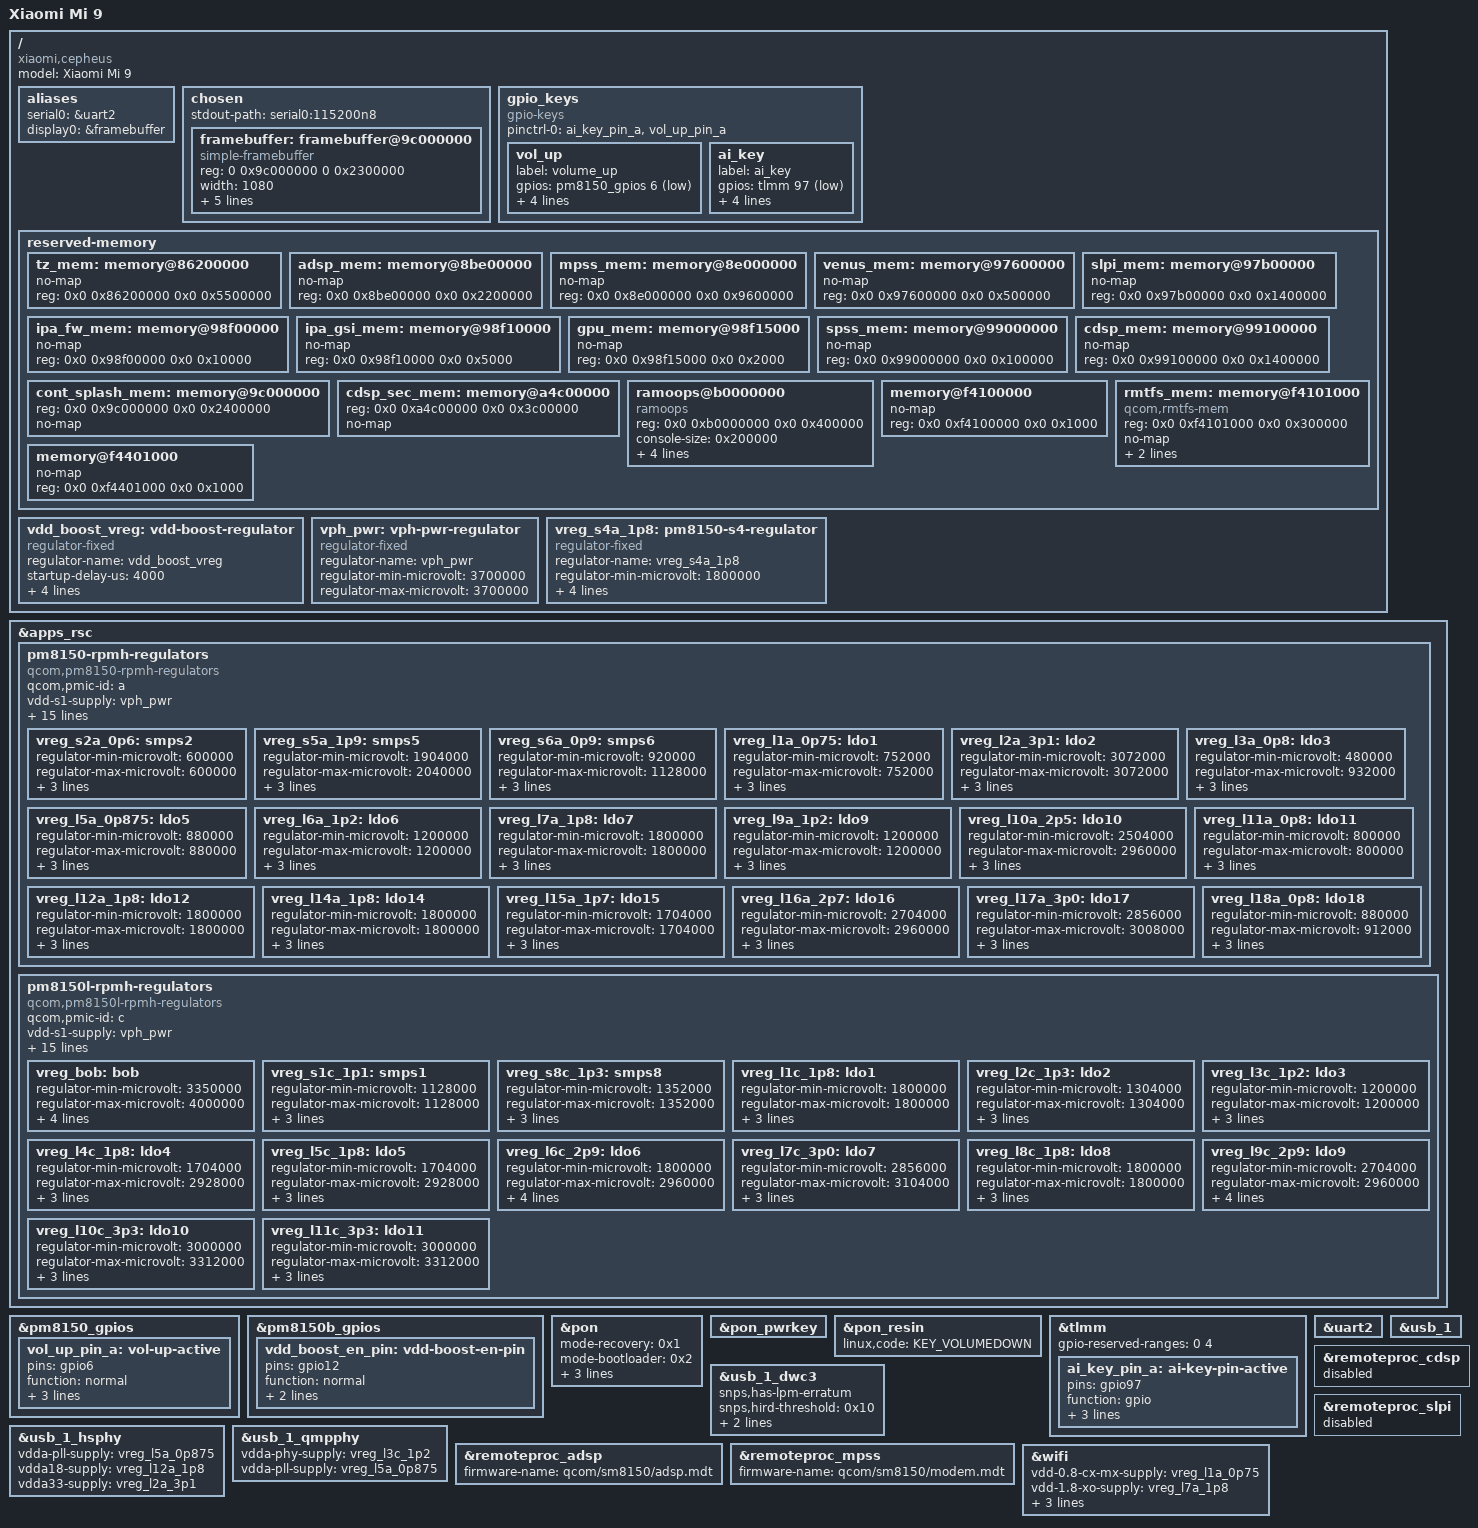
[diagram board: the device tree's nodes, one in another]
// SPDX-License-Identifier: BSD-3-Clause
/*
 * Copyright (c) 2021, Alexey Minnekhanov <alexeymin@postmarketos.org>
 */

/dts-v1/;

#include <dt-bindings/gpio/gpio.h>
#include <dt-bindings/input/input.h>
#include <dt-bindings/input/gpio-keys.h>
#include <dt-bindings/pinctrl/qcom,pmic-gpio.h>
#include <dt-bindings/regulator/qcom,rpmh-regulator.h>
#include "sm8150.dtsi"
#include "pm8150.dtsi"
#include "pm8150b.dtsi"
#include "pm8150l.dtsi"

/* 
 * Rewrite reserved memory maps inherited from sm8150.dtsi to match the ones
 * used on xiaomi-cepheus.
 * Note: this list is ordered by its memory address in sm8150.dtsi.
 */
/delete-node/ &tz_mem;      /* same address but larger, no place for rmtfs_mem! */
/delete-node/ &rmtfs_mem;   /* moved to completely different address */
/delete-node/ &adsp_mem;    /* same start address, but larger size */
/delete-node/ &mpss_mem;    /* same size, shifted higher, due to larger adsp_mem */
/delete-node/ &venus_mem;   /* same size, shifted higher */
/delete-node/ &slpi_mem;    /* same size, shifted higher */
/delete-node/ &ipa_fw_mem;  /* same size, shifted higher */
/delete-node/ &ipa_gsi_mem; /* same size, shifted higher */
/delete-node/ &gpu_mem;     /* same size, shifted higher */
/delete-node/ &spss_mem;    /* same size, shifted higher */
/delete-node/ &cdsp_mem;    /* same size, shifted higher */

/ {
	model = "Xiaomi Mi 9";
	compatible = "xiaomi,cepheus", "qcom,sm8150";

	aliases {
		serial0 = &uart2;
		display0 = &framebuffer;
	};

	chosen {
		#address-cells = <2>;
		#size-cells = <2>;
		ranges;

		stdout-path = "serial0:115200n8";

		framebuffer: framebuffer@9c000000 {
			compatible = "simple-framebuffer";
			reg = <0 0x9c000000 0 0x2300000>;
			width = <1080>;
			height = <2340>;
			stride = <(1080 * 4)>;
			format = "a8r8g8b8";
			/*
			 * That's (going to be) a lot of clocks, but it's necessary due
			 * to unused clk cleanup & no panel driver yet (& no dispcc either)..
			 */
			clocks = <&gcc GCC_DISP_HF_AXI_CLK>,
				 <&gcc GCC_DISP_SF_AXI_CLK>;
		};
	};

	gpio_keys {
		compatible = "gpio-keys";
		pinctrl-names = "default";
		pinctrl-0 = <&ai_key_pin_a &vol_up_pin_a>;
		
		vol_up {
			label = "volume_up";
			gpios = <&pm8150_gpios 6 GPIO_ACTIVE_LOW>;
			linux,input-type = <EV_KEY>;
			linux,code = <KEY_VOLUMEUP>;
			wakeup-source;
			debounce-interval = <15>;
		};

		ai_key {
			label = "ai_key";
			gpios = <&tlmm 97 GPIO_ACTIVE_LOW>;
			linux,input-type = <EV_KEY>;
			linux,code = <KEY_HOMEPAGE>; /* no AI key in Linux */
			wakeup-source;
			debounce-interval = <39>;
		};
	};

	reserved-memory {
		tz_mem: memory@86200000 {
			no-map;
			reg = <0x0 0x86200000 0x0 0x5500000>;
			phandle = <0x594>;
		};

		adsp_mem: memory@8be00000 {
			no-map;
			reg = <0x0 0x8be00000 0x0 0x2200000>;
		};

		mpss_mem: memory@8e000000 {
			no-map;
			reg = <0x0 0x8e000000 0x0 0x9600000>;
		};

		venus_mem: memory@97600000 {
			no-map;
			reg = <0x0 0x97600000 0x0 0x500000>;
		};

		slpi_mem: memory@97b00000 {
			no-map;
			reg = <0x0 0x97b00000 0x0 0x1400000>;
		};

		ipa_fw_mem: memory@98f00000 {
			no-map;
			reg = <0x0 0x98f00000 0x0 0x10000>;
		};

		ipa_gsi_mem: memory@98f10000 {
			no-map;
			reg = <0x0 0x98f10000 0x0 0x5000>;
		};

		gpu_mem: memory@98f15000 {
			no-map;
			reg = <0x0 0x98f15000 0x0 0x2000>;
		};

		spss_mem: memory@99000000 {
			no-map;
			reg = <0x0 0x99000000 0x0 0x100000>;
		};

		cdsp_mem: memory@99100000 {
			no-map;
			reg = <0x0 0x99100000 0x0 0x1400000>;
		};

		cont_splash_mem: memory@9c000000 {
			reg = <0x0 0x9c000000 0x0 0x2400000>;
			no-map;
		};

		cdsp_sec_mem: memory@a4c00000 {
			reg = <0x0 0xa4c00000 0x0 0x3c00000>;
			no-map;
		};

		ramoops@b0000000 {
			compatible = "ramoops";
			reg = <0x0 0xb0000000 0x0 0x400000>;
			console-size = <0x200000>;
			ecc-size = <0>;
			ftrace-size = <0>;
			pmsg-size = <0x200000>;
			record-size = <0>;
		};

		/* Downstream dynamically allocates rmtfs_mem region using
		 * dma_alloc_coherent and adds 4k guard pages before and after
		 * it to workaround some "XPU limitation". */
		/* rmtfs_lower_guard */
		memory@f4100000 {
			no-map;
			reg = <0x0 0xf4100000 0x0 0x1000>;
		};

		rmtfs_mem: memory@f4101000 {
			compatible = "qcom,rmtfs-mem";
			reg = <0x0 0xf4101000 0x0 0x300000>;
			no-map;

			qcom,client-id = <1>;
			qcom,vmid = <15>;
		};

		/* rmtfs_upper_guard */
		memory@f4401000 {
			no-map;
			reg = <0x0 0xf4401000 0x0 0x1000>;
		};
	};

	vdd_boost_vreg: vdd-boost-regulator {
		compatible = "regulator-fixed";
		regulator-name = "vdd_boost_vreg";
		startup-delay-us = <4000>;
		enable-active-high;
		regulator-always-on;
		gpio = <&pm8150b_gpios 5 GPIO_ACTIVE_HIGH>;
		pinctrl-names = "default";
		pinctrl-0 = <&vdd_boost_en_pin>;
	};

	vph_pwr: vph-pwr-regulator {
		compatible = "regulator-fixed";
		regulator-name = "vph_pwr";
		regulator-min-microvolt = <3700000>;
		regulator-max-microvolt = <3700000>;
	};

	/* S4 is modeled as a fixed regulator in vendor sources */
	vreg_s4a_1p8: pm8150-s4-regulator {
		compatible = "regulator-fixed";
		regulator-name = "vreg_s4a_1p8";

		regulator-min-microvolt = <1800000>;
		regulator-max-microvolt = <1800000>;

		regulator-always-on;
		regulator-boot-on;

		vin-supply = <&vph_pwr>;
	};
};

&apps_rsc {
	pm8150-rpmh-regulators {
		compatible = "qcom,pm8150-rpmh-regulators";
		qcom,pmic-id = "a";

		vdd-s1-supply = <&vph_pwr>;
		vdd-s2-supply = <&vph_pwr>;
		vdd-s3-supply = <&vph_pwr>;
		vdd-s4-supply = <&vph_pwr>;
		vdd-s5-supply = <&vph_pwr>;
		vdd-s6-supply = <&vph_pwr>;
		vdd-s7-supply = <&vph_pwr>;
		vdd-s8-supply = <&vph_pwr>;
		vdd-s9-supply = <&vph_pwr>;
		vdd-s10-supply = <&vph_pwr>;

		vdd-l1-l8-l11-supply = <&vreg_s6a_0p9>;
		vdd-l2-l10-supply = <&vreg_bob>;
		vdd-l3-l4-l5-l18-supply = <&vreg_s6a_0p9>;
		vdd-l6-l9-supply = <&vreg_s8c_1p3>;
		vdd-l7-l12-l14-l15-supply = <&vreg_s5a_1p9>;
		vdd-l13-l16-l17-supply = <&vreg_bob>;

		vreg_s2a_0p6: smps2 {
			regulator-min-microvolt = <600000>;
			regulator-max-microvolt = <600000>;
			regulator-initial-mode = <RPMH_REGULATOR_MODE_HPM>;
			regulator-name = "pm8150_s2a_0p6";
		};

		vreg_s5a_1p9: smps5 {
			regulator-min-microvolt = <1904000>;
			regulator-max-microvolt = <2040000>;
			regulator-initial-mode = <RPMH_REGULATOR_MODE_HPM>;
			regulator-name = "pm8150_s5a_0p6";
		};

		vreg_s6a_0p9: smps6 {
			regulator-min-microvolt = <920000>;
			regulator-max-microvolt = <1128000>;
			regulator-initial-mode = <RPMH_REGULATOR_MODE_HPM>;
			regulator-name = "pm8150_s6a_0p9";
		};

		vreg_l1a_0p75: ldo1 {
			regulator-min-microvolt = <752000>;
			regulator-max-microvolt = <752000>;
			regulator-initial-mode = <RPMH_REGULATOR_MODE_HPM>;
			regulator-name = "pm8150_l1a_0p75";
		};

		vreg_l2a_3p1: ldo2 {
			regulator-min-microvolt = <3072000>;
			regulator-max-microvolt = <3072000>;
			regulator-initial-mode = <RPMH_REGULATOR_MODE_HPM>;
			regulator-name = "pm8150_l2a_3p1";
		};

		vreg_l3a_0p8: ldo3 {
			regulator-min-microvolt = <480000>;
			regulator-max-microvolt = <932000>;
			regulator-initial-mode = <RPMH_REGULATOR_MODE_HPM>;
			regulator-name = "pm8150_l3a_0p8";
		};

		vreg_l5a_0p875: ldo5 {
			regulator-min-microvolt = <880000>;
			regulator-max-microvolt = <880000>;
			regulator-initial-mode = <RPMH_REGULATOR_MODE_HPM>;
			regulator-name = "pm8150_l5a_0p875";
		};

		vreg_l6a_1p2: ldo6 {
			regulator-min-microvolt = <1200000>;
			regulator-max-microvolt = <1200000>;
			regulator-initial-mode = <RPMH_REGULATOR_MODE_HPM>;
			regulator-name = "pm8150_l6a_1p2";
		};

		vreg_l7a_1p8: ldo7 {
			regulator-min-microvolt = <1800000>;
			regulator-max-microvolt = <1800000>;
			regulator-initial-mode = <RPMH_REGULATOR_MODE_HPM>;
			regulator-name = "pm8150_l7a_1p8";
		};

		vreg_l9a_1p2: ldo9 {
			regulator-min-microvolt = <1200000>;
			regulator-max-microvolt = <1200000>;
			regulator-initial-mode = <RPMH_REGULATOR_MODE_HPM>;
			regulator-name = "pm8150_l9a_1p2";
		};

		vreg_l10a_2p5: ldo10 {
			regulator-min-microvolt = <2504000>;
			regulator-max-microvolt = <2960000>;
			regulator-initial-mode = <RPMH_REGULATOR_MODE_HPM>;
			regulator-name = "pm8150_l10a_2p5";
		};

		vreg_l11a_0p8: ldo11 {
			regulator-min-microvolt = <800000>;
			regulator-max-microvolt = <800000>;
			regulator-initial-mode = <RPMH_REGULATOR_MODE_HPM>;
			regulator-name = "pm8150_l11a_0p8";
		};

		vreg_l12a_1p8: ldo12 {
			regulator-min-microvolt = <1800000>;
			regulator-max-microvolt = <1800000>;
			regulator-initial-mode = <RPMH_REGULATOR_MODE_HPM>;
			regulator-name = "pm8150_l12a_1p8";
		};

		/* L13 is unused, but min/max are 3000000 for it. */

		vreg_l14a_1p8: ldo14 {
			regulator-min-microvolt = <1800000>;
			regulator-max-microvolt = <1800000>;
			regulator-initial-mode = <RPMH_REGULATOR_MODE_HPM>;
			regulator-name = "pm8150_l14a_1p8";
		};

		vreg_l15a_1p7: ldo15 {
			regulator-min-microvolt = <1704000>;
			regulator-max-microvolt = <1704000>;
			regulator-initial-mode = <RPMH_REGULATOR_MODE_HPM>;
			regulator-name = "pm8150_l15a_1p7";
		};

		vreg_l16a_2p7: ldo16 {
			regulator-min-microvolt = <2704000>;
			regulator-max-microvolt = <2960000>;
			regulator-initial-mode = <RPMH_REGULATOR_MODE_HPM>;
			regulator-name = "pm8150_l16a_2p7";
		};

		vreg_l17a_3p0: ldo17 {
			regulator-min-microvolt = <2856000>;
			regulator-max-microvolt = <3008000>;
			regulator-initial-mode = <RPMH_REGULATOR_MODE_HPM>;
			regulator-name = "pm8150_l17a_3p0";
		};

		vreg_l18a_0p8: ldo18 {
			regulator-min-microvolt = <880000>;
			regulator-max-microvolt = <912000>;
			regulator-initial-mode = <RPMH_REGULATOR_MODE_HPM>;
			regulator-name = "pm8150_l18a_0p8";
		};
	};

	pm8150l-rpmh-regulators {
		compatible = "qcom,pm8150l-rpmh-regulators";
		qcom,pmic-id = "c";

		vdd-s1-supply = <&vph_pwr>;
		vdd-s2-supply = <&vph_pwr>;
		vdd-s3-supply = <&vph_pwr>;
		vdd-s4-supply = <&vph_pwr>;
		vdd-s5-supply = <&vph_pwr>;
		vdd-s6-supply = <&vph_pwr>;
		vdd-s7-supply = <&vph_pwr>;
		vdd-s8-supply = <&vph_pwr>;

		vdd-l1-l8-supply = <&vreg_s4a_1p8>;
		vdd-l2-l3-supply = <&vreg_s8c_1p3>;
		vdd-l4-l5-l6-supply = <&vreg_bob>;
		vdd-l7-l11-supply = <&vreg_bob>;
		vdd-l9-l10-supply = <&vreg_bob>;

		vdd-bob-supply = <&vph_pwr>;
		vdd-flash-supply = <&vreg_bob>;
		vdd-rgb-supply = <&vreg_bob>;

		vreg_bob: bob {
			regulator-min-microvolt = <3350000>;
			regulator-max-microvolt = <4000000>;
			/* tavil-slim-pgd will request 3300000 */
			regulator-initial-mode = <RPMH_REGULATOR_MODE_AUTO>;
			regulator-allow-bypass;
			regulator-name = "pm8150l_bob";
		};

		vreg_s1c_1p1: smps1 {
			regulator-min-microvolt = <1128000>;
			regulator-max-microvolt = <1128000>;
			regulator-initial-mode = <RPMH_REGULATOR_MODE_HPM>;
			regulator-name = "pm8150l_s1c_1p1";
		};

		vreg_s8c_1p3: smps8 {
			regulator-min-microvolt = <1352000>;
			regulator-max-microvolt = <1352000>;
			regulator-initial-mode = <RPMH_REGULATOR_MODE_HPM>;
			regulator-name = "pm8150l_s8c_1p3";
		};

		vreg_l1c_1p8: ldo1 {
			regulator-min-microvolt = <1800000>;
			regulator-max-microvolt = <1800000>;
			regulator-initial-mode = <RPMH_REGULATOR_MODE_HPM>;
			regulator-name = "pm8150l_l1c_1p8";
		};

		vreg_l2c_1p3: ldo2 {
			regulator-min-microvolt = <1304000>;
			regulator-max-microvolt = <1304000>;
			regulator-initial-mode = <RPMH_REGULATOR_MODE_HPM>;
			regulator-name = "pm8150l_l2c_1p3";
		};

		vreg_l3c_1p2: ldo3 {
			regulator-min-microvolt = <1200000>;
			regulator-max-microvolt = <1200000>;
			regulator-initial-mode = <RPMH_REGULATOR_MODE_HPM>;
			regulator-name = "pm8150l_l3c_1p2";
		};

		vreg_l4c_1p8: ldo4 {
			regulator-min-microvolt = <1704000>;
			regulator-max-microvolt = <2928000>;
			regulator-initial-mode = <RPMH_REGULATOR_MODE_HPM>;
			regulator-name = "pm8150l_l4c_1p8";
		};

		vreg_l5c_1p8: ldo5 {
			regulator-min-microvolt = <1704000>;
			regulator-max-microvolt = <2928000>;
			regulator-initial-mode = <RPMH_REGULATOR_MODE_HPM>;
			regulator-name = "pm8150l_l5c_1p8";
		};

		vreg_l6c_2p9: ldo6 {
			regulator-min-microvolt = <1800000>;
			regulator-max-microvolt = <2960000>;
			regulator-initial-mode = <RPMH_REGULATOR_MODE_HPM>;
			regulator-allow-set-load;
			regulator-name = "pm8150l_l6c_2p9";
		};

		vreg_l7c_3p0: ldo7 {
			regulator-min-microvolt = <2856000>;
			regulator-max-microvolt = <3104000>;
			regulator-initial-mode = <RPMH_REGULATOR_MODE_HPM>;
			regulator-name = "pm8150l_l7c_3p0";
		};

		vreg_l8c_1p8: ldo8 {
			regulator-min-microvolt = <1800000>;
			regulator-max-microvolt = <1800000>;
			regulator-initial-mode = <RPMH_REGULATOR_MODE_HPM>;
			regulator-name = "pm8150l_l8c_1p8";
		};

		vreg_l9c_2p9: ldo9 {
			regulator-min-microvolt = <2704000>;
			regulator-max-microvolt = <2960000>;
			regulator-initial-mode = <RPMH_REGULATOR_MODE_HPM>;
			regulator-allow-set-load;
			regulator-name = "pm8150l_l9c_2p9";
		};

		vreg_l10c_3p3: ldo10 {
			regulator-min-microvolt = <3000000>;
			regulator-max-microvolt = <3312000>;
			regulator-initial-mode = <RPMH_REGULATOR_MODE_HPM>;
			regulator-name = "pm8150l_l10c_3p3";
		};

		vreg_l11c_3p3: ldo11 {
			regulator-min-microvolt = <3000000>;
			regulator-max-microvolt = <3312000>;
			regulator-initial-mode = <RPMH_REGULATOR_MODE_HPM>;
			regulator-name = "pm8150l_l11c_3p3";
		};
	};
};

&pm8150_gpios {
	vol_up_pin_a: vol-up-active {
		pins = "gpio6";
		function = "normal";
		input-enable;
		bias-pull-up;
		qcom,drive-strength = <PMIC_GPIO_STRENGTH_NO>;
	};
};

&pm8150b_gpios {
	vdd_boost_en_pin: vdd-boost-en-pin {
		pins = "gpio12";
		function = "normal";
		output-low;
		qcom,drive-strength = <PMIC_GPIO_STRENGTH_HIGH>;
	};
};

&pon {
	mode-recovery = <0x1>;
	mode-bootloader = <0x2>;
	mode-rtc = <0x3>;
	mode-normal = <0x20>;
	mode-panic = <0x21>;
};

&pon_pwrkey {
	status = "okay";
};

&pon_resin {
	linux,code = <KEY_VOLUMEDOWN>;
	status = "okay";
};

&tlmm {
	/* gpios 0..3 are NFC spi, gpios 126..129 are FP spi */
	/* ★ 原来这里保留了 <126 4>（照抄主线 sm8150 板子的写法），但小米9 的
	 * 扬声器功放 CS35L41 就接在 secondary MI2S 的 126-129 上，保留会让
	 * pinctrl 无法申请这些脚（pin-126 -EINVAL）→ MI2S 永远配不上。
	 */
	gpio-reserved-ranges = <0 4>;

	ai_key_pin_a: ai-key-pin-active {
		pins = "gpio97";
		function = "gpio";
		drive-strength = <2>;
		bias-pull-up;
		input-enable;
	};
};

&uart2 {
	status = "okay";
};

&usb_1 {
	status = "okay";
};

&usb_1_dwc3 {
	snps,has-lpm-erratum;
	snps,hird-threshold = /bits/ 8 <0x10>;
	maximum-speed = "high-speed";
	dr_mode = "peripheral";
};

&usb_1_hsphy {
	status = "okay";
	vdda-pll-supply = <&vreg_l5a_0p875>;
	vdda18-supply = <&vreg_l12a_1p8>;
	vdda33-supply = <&vreg_l2a_3p1>;
};

&usb_1_qmpphy {
	status = "okay";
	vdda-phy-supply = <&vreg_l3c_1p2>;
	vdda-pll-supply = <&vreg_l5a_0p875>;
};

/*
 * ============================================================================
 *  Xiaomi Mi 9 (cepheus, SM8150) —— WCN3990 / ath10k_snoc WiFi 启用
 *  追加到 arch/arm64/boot/dts/qcom/sm8150-xiaomi-cepheus.dts 末尾
 *  ----------------------------------------------------------------------------
 *  为什么必须改 DTB（上机日志证据链）：
 *
 *  1) ath10k_snoc 驱动会执行：qmi_handle_init(AF_QIPCRTR) +
 *     qmi_add_lookup(WLFW) 去等一个叫 "WLFW" 的 QMI 服务；
 *  2) 这个服务不在 kernel 里，而是 ADSP 里跑的 WLAN 固件对外广播的；
 *  3) sm8150.dtsi 里 4 个 remoteproc（adsp/mpss/slpi/cdsp）默认
 *     status="disabled" → ADSP 从来没有被 Linux 拉起过
 *     → 手机上 /sys/class/rpmsg 和 /sys/bus/rpmsg/devices/ 都是空的
 *     → WLFW 服务永远不出现 → wlan0 永远不出现；
 *  4) 所以只加载 qrtr/qrtr-smd/qcom_glink_smem 模块是没用的：
 *     -517(EAFNOSUPPORT/EPROBE_DEFER) 会消失，但服务还是没人提供。
 *
 *  注：ADSP 起来之后仍需要 userspace 的 tqftpserv 给 DSP 喂
 *      qcom/sm8150/wlanmdsp.mbn，详见 ../README.md 第 3 阶段。
 *      DTB 只解决"把 ADSP 拉起来"这一环。
 * ============================================================================
 */

/* ADSP：WiFi 必需。它同时提供 lpass glink 端点，QRTR 的 IPCRTR 通道靠它 */
&remoteproc_adsp {
	status = "okay";
	/*
	 * 手上这台机器 /lib/firmware/qcom/sm8150/ 里是拆分固件：
	 *   adsp.mdt + adsp.b00 ~ adsp.b13
	 * 所以这里必须写 .mdt；不要写 .mbn（那是 linux-firmware 里的单体固件）。
	 */
	firmware-name = "qcom/sm8150/adsp.mdt";
};

/*
 * MPSS(modem)：**WiFi 不依赖它**，这里开着的唯一目的是当"诊断信号"
 *   —— 如果它也能到 running，说明 PAS + SCM + AOSS-QMP + QRTR 这套基础设施是好的。
 *
 * ⚠️ 注意：modem 起来后会通过 **rmtfs**（另一个服务，本包没带）要 EFS 分区，
 *    所以多半会在 dmesg 里刷 modem 相关的错误。**那些错误不影响 WiFi**。
 *    如果嫌吵，把下面这段整个注释掉（或改成 disabled）再重编内核即可。
 *    同理：如果 /lib/firmware/qcom/sm8150/modem.mdt 根本不存在，
 *    这里只会有一行 -ENOENT，也是无害的。
 */
&remoteproc_mpss {
	status = "okay";
	/* 同类：modem.mdt + modem.b00 ~ modem.b31 */
	firmware-name = "qcom/sm8150/modem.mdt";
};

/*
 * ★ 顺带记一个容易漏的依赖（本轮查证）：
 *   sm8150.dtsi 里 ADSP 节点带 `qcom,qmp = <&aoss_qmp>`
 *   —— SM8150 的 ADSP 必须通过 **AOSS QMP** 才能出复位。
 *   所以内核配置里必须有 CONFIG_QCOM_AOSS_QMP=y（我们的 .config 里是 y ✓）。
 *   如果哪天 dmesg 报 aoss_qmp 相关的 -EPROBE_DEFER，先查这一项。
 */

/*
 * CDSP / SLPI：与 WiFi 无关。手机上只有 adsp/modem 的固件，
 * 贸然打开只会让 remoteproc 加载失败刷错误日志，显式关掉。
 */
&remoteproc_cdsp {
	status = "disabled";
};

&remoteproc_slpi {
	status = "disabled";
};

&wifi {
	status = "okay";

	/*
	 * 四路供电。不写也能 probe（driver 会 fallback 到 dummy regulator，
	 * 上机日志里就是那 5 条 "supply ... not found, using dummy regulator"），
	 * 但 WCN3990 有可能因为没真正上电而加载固件失败，所以补全。
	 *
	 * 标签来自本文件上方 apps_rsc 里的 pm8150-rpmh-regulators /
	 * pm8150l-rpmh-regulators，与 sm8150-hdk / xiaomi-nabu / google-flame
	 * 的写法完全一致：
	 *   vdd-0.8-cx-mx -> PM8150  LDO1  (0.752V)
	 *   vdd-1.8-xo    -> PM8150  LDO7  (1.8V)
	 *   vdd-1.3-rfa   -> PM8150L LDO2  (1.304V)
	 *   vdd-3.3-ch0   -> PM8150L LDO11 (3.0~3.312V)
	 */
	vdd-0.8-cx-mx-supply = <&vreg_l1a_0p75>;
	vdd-1.8-xo-supply = <&vreg_l7a_1p8>;
	vdd-1.3-rfa-supply = <&vreg_l2c_1p3>;
	vdd-3.3-ch0-supply = <&vreg_l11c_3p3>;

	/*
	 * vdd-3.3-ch1 是较新内核给 WCN3990 追加的第 5 路可选电源轨
	 * （日志里也出现了它）。上游所有 sm8150 板子都没写这行；
	 * 如果 dmesg 里还在抱怨 ch1，就取消下面这行注释再试：
	 *
	 * vdd-3.3-ch1-supply = <&vreg_l10c_3p3>;
	 */

	/*
	 * board-2.bin 的变体名。linux-firmware 的
	 * ath10k/WCN3990/hw1.0/board-2.bin 里根本没有 "Xiaomi_cepheus"，
	 * 填不存在的名字不会编译/加载失败，但会退回通用条目。
	 * raphael（小米9T Pro）是同一颗 SM8150 + 同一代 WCN3990 模组，
	 * 用它是最接近的匹配；也可以改成 "Qualcomm_sm8150hdk" 或删掉整行。
	 */
	qcom,calibration-variant = "Xiaomi_raphael";
};
